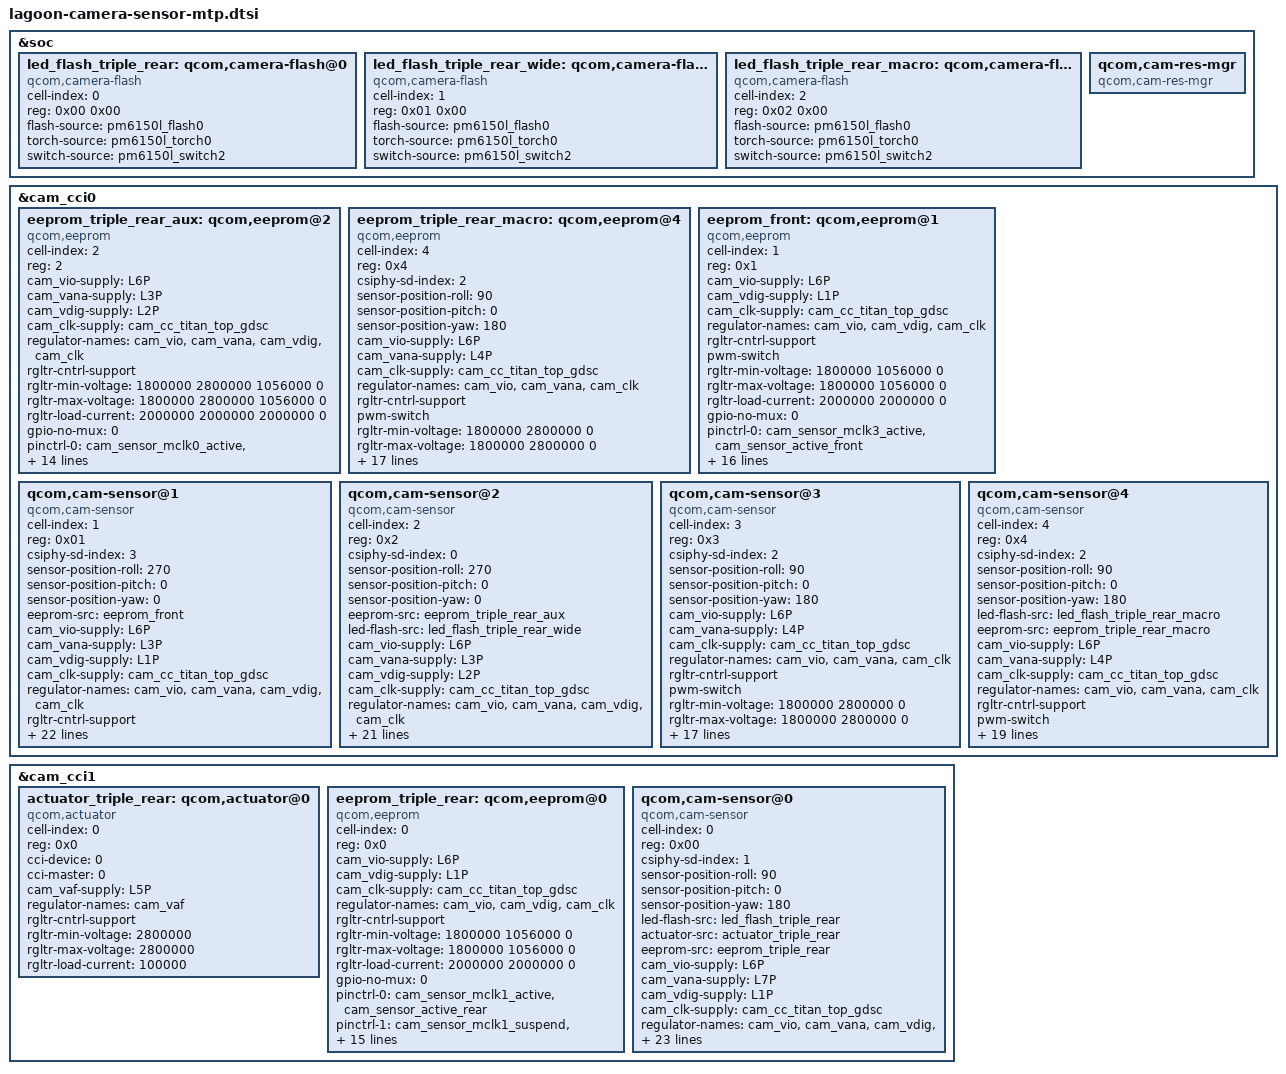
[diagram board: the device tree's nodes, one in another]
#include <dt-bindings/clock/qcom,camcc-lagoon.h>

&soc {
	led_flash_triple_rear: qcom,camera-flash@0 {
		cell-index = <0>;
		reg = <0x00 0x00>;
		compatible = "qcom,camera-flash";
		flash-source = <&pm6150l_flash0>;
		torch-source = <&pm6150l_torch0>;
		switch-source = <&pm6150l_switch2>;
		status = "ok";
	};
	led_flash_triple_rear_wide: qcom,camera-flash@1 {
		cell-index = <1>;
		reg = <0x01 0x00>;
		compatible = "qcom,camera-flash";
		flash-source = <&pm6150l_flash0>;
		torch-source = <&pm6150l_torch0>;
		switch-source = <&pm6150l_switch2>;
		status = "ok";
	};
	led_flash_triple_rear_macro: qcom,camera-flash@2 {
		cell-index = <2>;
		reg = <0x02 0x00>;
		compatible = "qcom,camera-flash";
		flash-source = <&pm6150l_flash0>;
		torch-source = <&pm6150l_torch0>;
		switch-source = <&pm6150l_switch2>;
		status = "ok";
	};

	qcom,cam-res-mgr {
		compatible = "qcom,cam-res-mgr";
		status = "ok";
	};
};

&cam_cci0 {
	eeprom_triple_rear_aux: qcom,eeprom@2 {
		cell-index = <2>;
		reg = <2>;
		compatible = "qcom,eeprom";
		cam_vio-supply = <&L6P>;
		cam_vana-supply = <&L3P>;
		cam_vdig-supply = <&L2P>;
		cam_clk-supply = <&cam_cc_titan_top_gdsc>;
		regulator-names = "cam_vio", "cam_vana", "cam_vdig",
			"cam_clk";
		rgltr-cntrl-support;
		rgltr-min-voltage = <1800000 2800000 1056000 0>;
		rgltr-max-voltage = <1800000 2800000 1056000 0>;
		rgltr-load-current = <2000000 2000000 2000000 0>;
		gpio-no-mux = <0>;
		pinctrl-names = "cam_default", "cam_suspend";
		pinctrl-0 = <&cam_sensor_mclk0_active
				 &cam_sensor_active_rear_aux>;
		pinctrl-1 = <&cam_sensor_mclk0_suspend
				 &cam_sensor_suspend_rear_aux>;
		gpios = <&tlmm 29 0>,
			<&tlmm 34 0>;
		gpio-reset = <1>;
		gpio-req-tbl-num = <0 1>;
		gpio-req-tbl-flags = <1 0>;
		gpio-req-tbl-label = "CAMIF_MCLK0",
					"CAM_RESET2";
		sensor-mode = <0>;
		cci-device = <0>;
		cci-master = <1>;
		status = "ok";
		clocks = <&camcc CAM_CC_MCLK0_CLK>;
		clock-names = "cam_clk";
		clock-cntl-level = "turbo";
		clock-rates = <19200000>;
	};
        eeprom_triple_rear_macro: qcom,eeprom@4 {
		cell-index = <4>;
		reg = <0x4>;
		compatible = "qcom,eeprom";
		csiphy-sd-index = <2>;
		sensor-position-roll = <90>;
		sensor-position-pitch = <0>;
		sensor-position-yaw = <180>;
		cam_vio-supply = <&L6P>;
		cam_vana-supply = <&L4P>;
		cam_clk-supply = <&cam_cc_titan_top_gdsc>;
		regulator-names = "cam_vio", "cam_vana", "cam_clk";
		rgltr-cntrl-support;
		pwm-switch;
		rgltr-min-voltage = <1800000 2800000 0>;
		rgltr-max-voltage = <1800000 2800000 0>;
		rgltr-load-current = <2000000 2000000 0>;
		gpio-no-mux = <0>;
		pinctrl-names = "cam_default", "cam_suspend";
		pinctrl-0 = <&cam_sensor_mclk4_active
				&cam_sensor_active_rear_aux1>;
		pinctrl-1 = <&cam_sensor_mclk4_suspend
				&cam_sensor_suspend_rear_aux1>;
		gpios = <&tlmm 33 0>,
			<&tlmm 36 0>;
		gpio-reset = <1>;
		gpio-req-tbl-num = <0 1>;
		gpio-req-tbl-flags = <1 0>;
		gpio-req-tbl-label = "CAMIF_MCLK4",
					"CAM_RESET4";
		sensor-mode = <0>;
		cci-device = <0>;
		cci-master = <0>;
		status = "ok";
		clocks = <&camcc CAM_CC_MCLK4_CLK>;
		clock-names = "cam_clk";
		clock-cntl-level = "turbo";
		clock-rates = <24000000>;
	};
	eeprom_front: qcom,eeprom@1 {
		cell-index = <1>;
		reg = <0x1>;
		compatible = "qcom,eeprom";
		cam_vio-supply = <&L6P>;
		cam_vdig-supply = <&L1P>;
		cam_clk-supply = <&cam_cc_titan_top_gdsc>;
		regulator-names = "cam_vio", "cam_vdig",
			"cam_clk";
		rgltr-cntrl-support;
		pwm-switch;
		rgltr-min-voltage = <1800000 1056000 0>;
		rgltr-max-voltage = <1800000 1056000 0>;
		rgltr-load-current = <2000000 2000000 0>;
		gpio-no-mux = <0>;
		pinctrl-names = "cam_default", "cam_suspend";
		pinctrl-0 = <&cam_sensor_mclk3_active
			&cam_sensor_active_front>;
		pinctrl-1 = <&cam_sensor_mclk3_suspend
			&cam_sensor_suspend_front>;
		gpios = <&tlmm 32 0>,
			<&tlmm 37 0>,
			<&tlmm 24 0>;
		gpio-reset = <1>;
		gpio-custom1 = <2>;
		gpio-req-tbl-num = <0 1 2>;
		gpio-req-tbl-flags = <1 0 0>;
		gpio-req-tbl-label = "CAMIF_MCLK3",
					"CAM_RESET1",
					"CAM_VANA1";
		sensor-position = <1>;
		sensor-mode = <0>;
		cci-device = <0>;
		cci-master = <1>;
		status = "ok";
		clocks = <&camcc CAM_CC_MCLK3_CLK>;
		clock-names = "cam_clk";
		clock-cntl-level = "turbo";
		clock-rates = <19200000>;
	};
//+bug550748, xiaojianhua.wt, ADD, 2020.04.30, porting camera hi864, gc02m1b, ov02b10.
	/* front sensor */
	qcom,cam-sensor@1 {
		cell-index = <1>;
		compatible = "qcom,cam-sensor";
		reg = <0x01>;
		csiphy-sd-index = <3>;
		sensor-position-roll = <270>;
		sensor-position-pitch = <0>;
		sensor-position-yaw = <0>;
		eeprom-src = <&eeprom_front>;
		cam_vio-supply = <&L6P>;
		cam_vana-supply = <&L3P>;
		cam_vdig-supply = <&L1P>;
		cam_clk-supply = <&cam_cc_titan_top_gdsc>;
		regulator-names = "cam_vio", "cam_vana", "cam_vdig",
			"cam_clk";
		rgltr-cntrl-support;
		pwm-switch;
		rgltr-min-voltage = <1800000 2850000 1100000 0>;
		rgltr-max-voltage = <1800000 2850000 1100000 0>;
		rgltr-load-current = <2000000 2000000 2000000 0>;
		gpio-no-mux = <0>;
		pinctrl-names = "cam_default", "cam_suspend";
		pinctrl-0 = <&cam_sensor_mclk3_active
			&cam_sensor_active_front>;
		pinctrl-1 = <&cam_sensor_mclk3_suspend
			&cam_sensor_suspend_front>;
		gpios = <&tlmm 32 0>,
			<&tlmm 37 0>,
			<&tlmm 24 0>;
		gpio-reset = <1>;
		gpio-custom1 = <2>;
		gpio-req-tbl-num = <0 1 2>;
		gpio-req-tbl-flags = <1 0 0>;
		gpio-req-tbl-label = "CAMIF_MCLK3",
					"CAM_RESET1",
					"CAM_VANA1";
		sensor-mode = <0>;
		cci-device = <0>;
		cci-master = <1>;
		status = "ok";
		clocks = <&camcc CAM_CC_MCLK3_CLK>;
		clock-names = "cam_clk";
		clock-cntl-level = "turbo";
		clock-rates = <19200000>;
	};
	/* wide sensor */
	qcom,cam-sensor@2 {
		cell-index = <2>;
		compatible = "qcom,cam-sensor";
		reg = <0x2>;
		csiphy-sd-index = <0>;
		sensor-position-roll = <270>;
		sensor-position-pitch = <0>;
		sensor-position-yaw = <0>;
		eeprom-src = <&eeprom_triple_rear_aux>;
		led-flash-src = <&led_flash_triple_rear_wide>;
		cam_vio-supply = <&L6P>;
		cam_vana-supply = <&L3P>;
		cam_vdig-supply = <&L2P>;
		cam_clk-supply = <&cam_cc_titan_top_gdsc>;
		regulator-names = "cam_vio", "cam_vana", "cam_vdig",
			"cam_clk";
		rgltr-cntrl-support;
		pwm-switch;
		rgltr-min-voltage = <1800000 2800000 1200000 0>;
		rgltr-max-voltage = <1800000 2800000 1200000 0>;
		rgltr-load-current = <2000000 2000000 2000000 0>;
		gpio-no-mux = <0>;
		pinctrl-names = "cam_default", "cam_suspend";
		pinctrl-0 = <&cam_sensor_mclk0_active
				 &cam_sensor_active_rear_aux>;
		pinctrl-1 = <&cam_sensor_mclk0_suspend
				 &cam_sensor_suspend_rear_aux>;
		gpios = <&tlmm 29 0>,
			<&tlmm 34 0>;
		gpio-reset = <1>;
		gpio-req-tbl-num = <0 1>;
		gpio-req-tbl-flags = <1 0>;
		gpio-req-tbl-label = "CAMIF_MCLK0",
					"CAM_RESET2";
		sensor-mode = <0>;
		cci-device = <0>;
		cci-master = <1>;
		status = "ok";
		clocks = <&camcc CAM_CC_MCLK0_CLK>;
		clock-names = "cam_clk";
		clock-cntl-level = "turbo";
		clock-rates = <19200000>;
	};

	/* mono sensor */
	qcom,cam-sensor@3 {
		cell-index = <3>;
		compatible = "qcom,cam-sensor";
		reg = <0x3>;
		csiphy-sd-index = <2>;
		sensor-position-roll = <90>;
		sensor-position-pitch = <0>;
		sensor-position-yaw = <180>;
		//led-flash-src = <&led_flash_triple_rear>;
		//actuator-src = <&actuator_triple_rear>;
		//eeprom-src = <&eeprom_triple_rear>;
		cam_vio-supply = <&L6P>;
		cam_vana-supply = <&L4P>;
		cam_clk-supply = <&cam_cc_titan_top_gdsc>;
		regulator-names = "cam_vio", "cam_vana", "cam_clk";
		rgltr-cntrl-support;
		pwm-switch;
		rgltr-min-voltage = <1800000 2800000 0>;
		rgltr-max-voltage = <1800000 2800000 0>;
		rgltr-load-current = <2000000 2000000 0>;
		gpio-no-mux = <0>;
		pinctrl-names = "cam_default", "cam_suspend";
		pinctrl-0 = <&cam_sensor_mclk2_active
				&cam_sensor_active_rear_aux2>;
		pinctrl-1 = <&cam_sensor_mclk2_suspend
				&cam_sensor_suspend_rear_aux2>;
		gpios = <&tlmm 31 0>,
			<&tlmm 38 0>;
		gpio-standby = <1>;//PWDN
		gpio-req-tbl-num = <0 1>;
		gpio-req-tbl-flags = <1 0>;
		gpio-req-tbl-label = "CAMIF_MCLK2",
					"CAM_STANDBY";
		sensor-mode = <0>;
		cci-device = <0>;
		cci-master = <0>;
		status = "ok";
		clocks = <&camcc CAM_CC_MCLK2_CLK>;
		clock-names = "cam_clk";
		clock-cntl-level = "turbo";
		clock-rates = <19200000>;
	};

	/* macro sensor */
	qcom,cam-sensor@4 {
		cell-index = <4>;
		compatible = "qcom,cam-sensor";
		reg = <0x4>;
		csiphy-sd-index = <2>;
		sensor-position-roll = <90>;
		sensor-position-pitch = <0>;
		sensor-position-yaw = <180>;
		led-flash-src = <&led_flash_triple_rear_macro>;
		//actuator-src = <&actuator_triple_rear>;
		eeprom-src = <&eeprom_triple_rear_macro>;
		cam_vio-supply = <&L6P>;
		cam_vana-supply = <&L4P>;
		cam_clk-supply = <&cam_cc_titan_top_gdsc>;
		regulator-names = "cam_vio", "cam_vana", "cam_clk";
		rgltr-cntrl-support;
		pwm-switch;
		rgltr-min-voltage = <1800000 2800000 0>;
		rgltr-max-voltage = <1800000 2800000 0>;
		rgltr-load-current = <2000000 2000000 0>;
		gpio-no-mux = <0>;
		pinctrl-names = "cam_default", "cam_suspend";
		pinctrl-0 = <&cam_sensor_mclk4_active
				&cam_sensor_active_rear_aux1>;
		pinctrl-1 = <&cam_sensor_mclk4_suspend
				&cam_sensor_suspend_rear_aux1>;
		gpios = <&tlmm 33 0>,
			<&tlmm 36 0>;
		gpio-reset = <1>;
		gpio-req-tbl-num = <0 1>;
		gpio-req-tbl-flags = <1 0>;
		gpio-req-tbl-label = "CAMIF_MCLK4",
					"CAM_RESET4";
		sensor-mode = <0>;
		cci-device = <0>;
		cci-master = <0>;
		status = "ok";
		clocks = <&camcc CAM_CC_MCLK4_CLK>;
		clock-names = "cam_clk";
		clock-cntl-level = "turbo";
		clock-rates = <19200000>;
	};
//-bug550748, xiaojianhua.wt, ADD, 2020.04.30, porting camera hi864, gc02m1b, ov02b10.
};

&cam_cci1 {
	actuator_triple_rear: qcom,actuator@0 {
		cell-index = <0>;
		reg = <0x0>;
		compatible = "qcom,actuator";
		cci-device = <0>;
		cci-master = <0>;
		cam_vaf-supply = <&L5P>;
		regulator-names = "cam_vaf";
		rgltr-cntrl-support;
		rgltr-min-voltage = <2800000>;
		rgltr-max-voltage = <2800000>;
		rgltr-load-current = <100000>;
		status = "ok";
	};

	eeprom_triple_rear: qcom,eeprom@0 {
		cell-index = <0>;
		reg = <0x0>;
		compatible = "qcom,eeprom";
		cam_vio-supply = <&L6P>;
		cam_vdig-supply = <&L1P>;
		cam_clk-supply = <&cam_cc_titan_top_gdsc>;
		regulator-names = "cam_vio", "cam_vdig",
			"cam_clk";
		rgltr-cntrl-support;
		rgltr-min-voltage = <1800000 1056000 0>;
		rgltr-max-voltage = <1800000 1056000 0>;
		rgltr-load-current = <2000000 2000000 0>;
		gpio-no-mux = <0>;
		pinctrl-names = "cam_default", "cam_suspend";
		pinctrl-0 = <&cam_sensor_mclk1_active
				 &cam_sensor_active_rear>;
		pinctrl-1 = <&cam_sensor_mclk1_suspend
				 &cam_sensor_suspend_rear>;
		gpios = <&tlmm 30 0>,
			<&tlmm 35 0>,
			<&tlmm 51 0>;
		gpio-reset = <1>;
		gpio-custom1 = <2>;
		gpio-req-tbl-num = <0 1 2>;
		gpio-req-tbl-flags = <1 0 0>;
		gpio-req-tbl-label = "CAMIF_MCLK1",
					"CAM_RESET0",
					"CAM_VANA0";
		sensor-position = <0>;
		sensor-mode = <0>;
		cci-device = <1>;
		cci-master = <0>;
		status = "ok";
		clocks = <&camcc CAM_CC_MCLK1_CLK>;
		clock-names = "cam_clk";
		clock-cntl-level = "turbo";
		clock-rates = <19200000>;
	};

//+bug550748, xiaojianhua.wt, ADD, 2020.04.30, porting camera hi864, gc02m1b, ov02b10.
	/* main sensor */
	qcom,cam-sensor@0 {
		cell-index = <0>;
		compatible = "qcom,cam-sensor";
		reg = <0x00>;
		csiphy-sd-index = <1>;
		sensor-position-roll = <90>;
		sensor-position-pitch = <0>;
		sensor-position-yaw = <180>;
		led-flash-src = <&led_flash_triple_rear>;
		actuator-src = <&actuator_triple_rear>;
		eeprom-src = <&eeprom_triple_rear>;
		cam_vio-supply = <&L6P>;
		cam_vana-supply = <&L7P>;
		cam_vdig-supply = <&L1P>;
		cam_clk-supply = <&cam_cc_titan_top_gdsc>;
		regulator-names = "cam_vio", "cam_vana", "cam_vdig",
			"cam_clk";
		rgltr-cntrl-support;
		rgltr-min-voltage = <1800000 2800000 1100000 0>;
		rgltr-max-voltage = <1800000 2800000 1100000 0>;
		rgltr-load-current = <2000000 2000000 2000000 0>;
		gpio-no-mux = <0>;
		pinctrl-names = "cam_default", "cam_suspend";
		pinctrl-0 = <&cam_sensor_mclk1_active
				 &cam_sensor_active_rear>;
		pinctrl-1 = <&cam_sensor_mclk1_suspend
				 &cam_sensor_suspend_rear>;
		gpios = <&tlmm 30 0>,
			<&tlmm 35 0>,
			<&tlmm 51 0>;
		gpio-reset = <1>;
		gpio-custom1 = <2>;
		gpio-req-tbl-num = <0 1 2>;
		gpio-req-tbl-flags = <1 0 0>;
		gpio-req-tbl-label = "CAMIF_MCLK1",
					"CAM_RESET0",
					"CAM_VANA0";
		sensor-mode = <0>;
		cci-device = <1>;
		cci-master = <0>;
		status = "ok";
		clocks = <&camcc CAM_CC_MCLK1_CLK>;
		clock-names = "cam_clk";
		clock-cntl-level = "turbo";
		clock-rates = <19200000>;
	};
//-bug550748, xiaojianhua.wt, ADD, 2020.04.30, porting camera hi864, gc02m1b, ov02b10.
};
